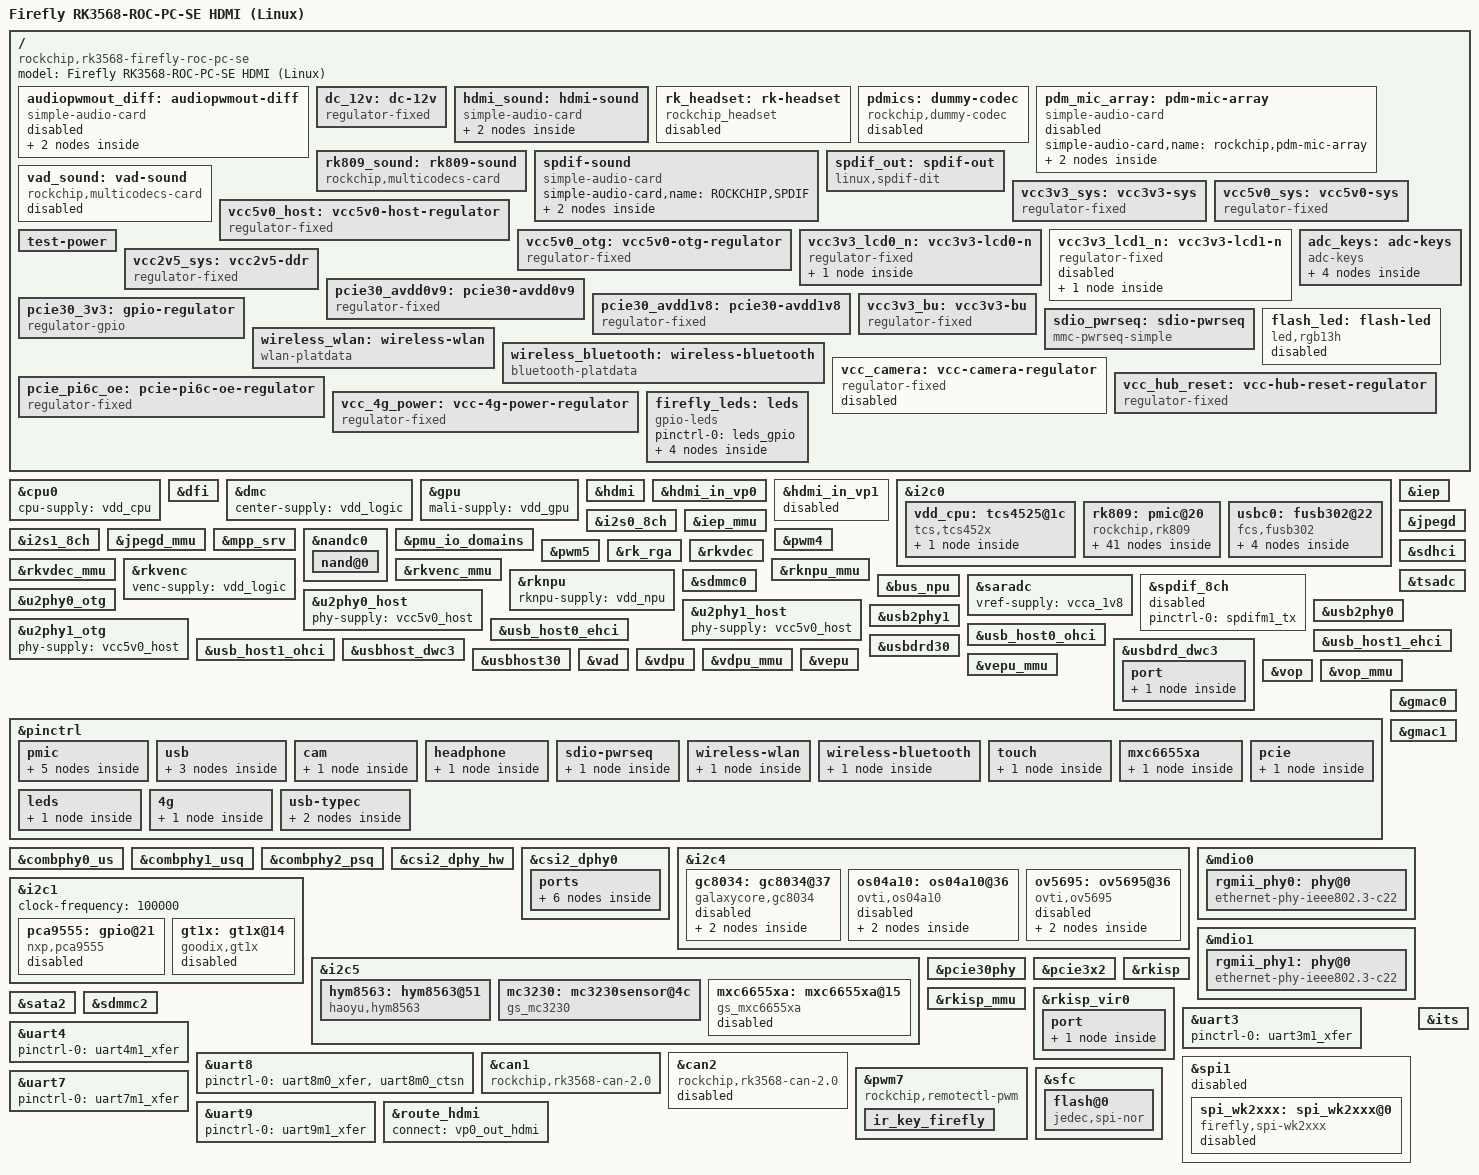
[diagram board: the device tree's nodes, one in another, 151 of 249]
// SPDX-License-Identifier: (GPL-2.0+ OR MIT)
/*
 * Copyright (c) 2020 Rockchip Electronics Co., Ltd.
 *
 */

/dts-v1/;

#include "dt-bindings/usb/pd.h"
#include <dt-bindings/pwm/pwm.h>
#include <dt-bindings/gpio/gpio.h>
#include <dt-bindings/input/rk-input.h>
#include <dt-bindings/pinctrl/rockchip.h>
#include <dt-bindings/display/rockchip_vop.h>
#include <dt-bindings/display/drm_mipi_dsi.h>
#include <dt-bindings/sensor-dev.h>
#include "rk3568.dtsi"
#include "rk3568-linux.dtsi"

/ {
	model = "Firefly RK3568-ROC-PC-SE HDMI (Linux)";
	compatible = "rockchip,rk3568-firefly-roc-pc-se", "rockchip,rk3568";

	audiopwmout_diff: audiopwmout-diff {
		status = "disabled";
		compatible = "simple-audio-card";
		simple-audio-card,format = "i2s";
		simple-audio-card,name = "rockchip,audiopwmout-diff";
		simple-audio-card,mclk-fs = <256>;
		simple-audio-card,bitclock-master = <&master>;
		simple-audio-card,frame-master = <&master>;
		simple-audio-card,cpu {
			sound-dai = <&i2s3_2ch>;
		};
		master: simple-audio-card,codec {
			sound-dai = <&dig_acodec>;
		};
	};

	dc_12v: dc-12v {
		compatible = "regulator-fixed";
		regulator-name = "dc_12v";
		regulator-always-on;
		regulator-boot-on;
		regulator-min-microvolt = <12000000>;
		regulator-max-microvolt = <12000000>;
	};

	hdmi_sound: hdmi-sound {
		compatible = "simple-audio-card";
		simple-audio-card,format = "i2s";
		simple-audio-card,mclk-fs = <128>;
		simple-audio-card,name = "rockchip,hdmi";
		status = "disabled";

		simple-audio-card,cpu {
				sound-dai = <&i2s0_8ch>;
		};
		simple-audio-card,codec {
				sound-dai = <&hdmi>;
		};
	};

	rk_headset: rk-headset {
		status = "disabled";
		compatible = "rockchip_headset";
		headset_gpio = <&gpio3 RK_PC2 GPIO_ACTIVE_LOW>;
		pinctrl-names = "default";
		pinctrl-0 = <&hp_det>;
	};

	pdmics: dummy-codec {
		status = "disabled";
		compatible = "rockchip,dummy-codec";
		#sound-dai-cells = <0>;
	};

	pdm_mic_array: pdm-mic-array {
		status = "disabled";
		compatible = "simple-audio-card";
		simple-audio-card,name = "rockchip,pdm-mic-array";
		simple-audio-card,cpu {
			sound-dai = <&pdm>;
		};
		simple-audio-card,codec {
			sound-dai = <&pdmics>;
		};
	};

	rk809_sound: rk809-sound {
		status = "okay";
		compatible = "rockchip,multicodecs-card";
		rockchip,card-name = "rockchip-rk809";
		rockchip,format = "i2s";
		rockchip,mclk-fs = <256>;
		rockchip,cpu = <&i2s1_8ch>;
		rockchip,codec = <&rk809_codec>;
	};

	spdif-sound {
		status = "okay";
		compatible = "simple-audio-card";
		simple-audio-card,name = "ROCKCHIP,SPDIF";
		simple-audio-card,cpu {
				sound-dai = <&spdif_8ch>;
		};
		simple-audio-card,codec {
				sound-dai = <&spdif_out>;
		};
	};

	spdif_out: spdif-out {
			status = "okay";
			compatible = "linux,spdif-dit";
			#sound-dai-cells = <0>;
	};

	vad_sound: vad-sound {
		status = "disabled";
		compatible = "rockchip,multicodecs-card";
		rockchip,card-name = "rockchip,rk3568-vad";
		rockchip,cpu = <&i2s1_8ch>;
		rockchip,codec = <&rk809_codec>, <&vad>;
	};

	vcc3v3_sys: vcc3v3-sys {
		compatible = "regulator-fixed";
		regulator-name = "vcc3v3_sys";
		regulator-always-on;
		regulator-boot-on;
		regulator-min-microvolt = <3300000>;
		regulator-max-microvolt = <3300000>;
		vin-supply = <&dc_12v>;
	};

	vcc5v0_sys: vcc5v0-sys {
		compatible = "regulator-fixed";
		regulator-name = "vcc5v0_sys";
		regulator-always-on;
		regulator-boot-on;
		regulator-min-microvolt = <5000000>;
		regulator-max-microvolt = <5000000>;
		vin-supply = <&dc_12v>;
	};

	vcc5v0_host: vcc5v0-host-regulator {
		compatible = "regulator-fixed";
		enable-active-high;
		gpio = <&gpio0 RK_PD6 GPIO_ACTIVE_HIGH>;
		pinctrl-names = "default";
		pinctrl-0 = <&vcc5v0_host_en>;
		regulator-name = "vcc5v0_host";
		regulator-always-on;
		regulator-boot-on;
	};

	vcc5v0_otg: vcc5v0-otg-regulator {
		compatible = "regulator-fixed";
		enable-active-high;
		gpio = <&gpio0 RK_PA5 GPIO_ACTIVE_HIGH>;
		pinctrl-names = "default";
		pinctrl-0 = <&vcc5v0_otg_en>;
		regulator-name = "vcc5v0_otg";
	};

	vcc3v3_lcd0_n: vcc3v3-lcd0-n {
		compatible = "regulator-fixed";
		regulator-name = "vcc3v3_lcd0_n";
		regulator-boot-on;
		regulator-state-mem {
			regulator-off-in-suspend;
		};
	};

	vcc3v3_lcd1_n: vcc3v3-lcd1-n {
		compatible = "regulator-fixed";
		regulator-name = "vcc3v3_lcd1_n";
		regulator-boot-on;
		regulator-state-mem {
			regulator-off-in-suspend;
		};
	};

	test-power {
		status = "okay";
	};
	
	adc_keys: adc-keys {
		compatible = "adc-keys";
		io-channels = <&saradc 0>;
		io-channel-names = "buttons";
		keyup-threshold-microvolt = <1800000>;
		poll-interval = <100>;

		recovery-key {
			label = "F12";
			linux,code = <KEY_F12>;
			press-threshold-microvolt = <1750>;
		};

		vol-down-key {
			label = "volume down";
			linux,code = <KEY_VOLUMEDOWN>;
			press-threshold-microvolt = <297500>;
		};

		menu-key {
			label = "menu";
			linux,code = <KEY_MENU>;
			press-threshold-microvolt = <980000>;
		};

		back-key {
			label = "back";
			linux,code = <KEY_BACK>;
			press-threshold-microvolt = <1305500>;
		};
	};

	vcc2v5_sys: vcc2v5-ddr {
		compatible = "regulator-fixed";
		regulator-name = "vcc2v5-sys";
		regulator-always-on;
		regulator-boot-on;
		regulator-min-microvolt = <2500000>;
		regulator-max-microvolt = <2500000>;
		vin-supply = <&vcc3v3_sys>;
	};

	pcie30_avdd0v9: pcie30-avdd0v9 {
		compatible = "regulator-fixed";
		regulator-name = "pcie30_avdd0v9";
		regulator-always-on;
		regulator-boot-on;
		regulator-min-microvolt = <900000>;
		regulator-max-microvolt = <900000>;
		vin-supply = <&vcc3v3_sys>;
	};

	pcie30_avdd1v8: pcie30-avdd1v8 {
		compatible = "regulator-fixed";
		regulator-name = "pcie30_avdd1v8";
		regulator-always-on;
		regulator-boot-on;
		regulator-min-microvolt = <1800000>;
		regulator-max-microvolt = <1800000>;
		vin-supply = <&vcc3v3_sys>;
	};

	pcie30_3v3: gpio-regulator {
		compatible = "regulator-gpio";
		regulator-name = "pcie30_3v3";
		regulator-min-microvolt = <100000>;
		regulator-max-microvolt = <3300000>;
		gpios = <&gpio0 RK_PD4 GPIO_ACTIVE_HIGH>;
		gpios-states = <0x1>;
		states = <100000 0x0
			  3300000 0x1>;
	};

	vcc3v3_bu: vcc3v3-bu {
		compatible = "regulator-fixed";
		regulator-name = "vcc3v3_bu";
		regulator-always-on;
		regulator-boot-on;
		regulator-min-microvolt = <3300000>;
		regulator-max-microvolt = <3300000>;
		vin-supply = <&vcc5v0_sys>;
	};

	sdio_pwrseq: sdio-pwrseq {
		compatible = "mmc-pwrseq-simple";
		clocks = <&rk809 1>;
		clock-names = "ext_clock";
		pinctrl-names = "default";
		pinctrl-0 = <&wifi_enable_h>;
		/*
			* On the module itself this is one of these (depending
			* on the actual card populated):
			* - SDIO_RESET_L_WL_REG_ON
			* - PDN (power down when low)
		*/
		post-power-on-delay-ms = <200>;
		reset-gpios = <&gpio3 RK_PD5 GPIO_ACTIVE_LOW>;
	};

	wireless_wlan: wireless-wlan {
		compatible = "wlan-platdata";
		rockchip,grf = <&grf>;
		wifi_chip_type = "ap6398s";
		pinctrl-names = "default";
		pinctrl-0 = <&wifi_host_wake_irq>;
		WIFI,host_wake_irq = <&gpio3 RK_PD4 GPIO_ACTIVE_HIGH>;
		status = "disabled";
	};

	wireless_bluetooth: wireless-bluetooth {
		compatible = "bluetooth-platdata";
		clocks = <&rk809 1>;
		clock-names = "ext_clock";
		//wifi-bt-power-toggle;
		uart_rts_gpios = <&gpio2 RK_PB1 GPIO_ACTIVE_LOW>;
		pinctrl-names = "default", "rts_gpio";
		pinctrl-0 = <&uart8m0_rtsn>;
		pinctrl-1 = <&uart8_gpios>;
		BT,reset_gpio    = <&gpio3 RK_PA0 GPIO_ACTIVE_HIGH>;
		BT,wake_gpio     = <&gpio3 RK_PA1 GPIO_ACTIVE_HIGH>;
		BT,wake_host_irq = <&gpio3 RK_PA2 GPIO_ACTIVE_HIGH>;
		status = "disabled";
	};

	flash_led: flash-led {
		compatible = "led,rgb13h";
		label = "pwm-flash-led";
		led-max-microamp = <20000>;
		flash-max-microamp = <20000>;
		flash-max-timeout-us = <1000000>;
		pwms = <&pwm11 0 25000 0>;
		rockchip,camera-module-index = <1>;
		rockchip,camera-module-facing = "front";
		status = "disabled";
	};

	vcc_camera: vcc-camera-regulator {
		compatible = "regulator-fixed";
		//gpio = <&pca9555 0 GPIO_ACTIVE_HIGH>;
		gpio = <&pca9555 3 GPIO_ACTIVE_HIGH>;
		pinctrl-names = "default";
		pinctrl-0 = <&vcc_cam>;
		regulator-name = "vcc_camera";
		enable-active-high;
		status = "disabled";
	};
	
	vcc5v0_host: vcc5v0-host-regulator {
		compatible = "regulator-fixed";
		enable-active-high;
		gpio = <&gpio0 RK_PA6 GPIO_ACTIVE_HIGH>;
		pinctrl-names = "default";
		pinctrl-0 = <&vcc5v0_host_en>;
		regulator-name = "vcc5v0_host";
		regulator-always-on;
	};

    vcc_hub_reset: vcc-hub-reset-regulator {
        compatible = "regulator-fixed";
        enable-active-high;
        gpio = <&gpio1 RK_PA4 GPIO_ACTIVE_HIGH>;
        pinctrl-names = "default";
        pinctrl-0 = <&vcc_hub_reset_en>;
        regulator-name = "vcc_hub_reset_en";
        regulator-always-on;
    };

    pcie_pi6c_oe: pcie-pi6c-oe-regulator {
        compatible = "regulator-fixed";
        //enable-active-high;
        gpio = <&gpio3 RK_PA7 GPIO_ACTIVE_LOW>;
        pinctrl-names = "default";
        pinctrl-0 = <&pcie_pi6c_oe_en>;
        regulator-name = "pcie_pi6c_oe_en";
        regulator-always-on;
    };

    vcc_4g_power: vcc-4g-power-regulator {
        compatible = "regulator-fixed";
        enable-active-high;
        gpio = <&gpio3 RK_PA3 GPIO_ACTIVE_HIGH>;
        pinctrl-names = "default";
        pinctrl-0 = <&vcc_4g_power_en>;
        regulator-name = "vcc_4g_power_en";
        regulator-always-on;
    };

    firefly_leds: leds {
        status = "okay";
        compatible = "gpio-leds";
        pinctrl-names = "default";
        pinctrl-0 =<&leds_gpio>;

        power_led: power {
            label = "firefly:blue:power";
            linux,default-trigger = "ir-power-click";
            default-state = "on";
            gpios = <&gpio1 RK_PB2 GPIO_ACTIVE_HIGH>;
        };

        user_led: user {
            label = "firefly:yellow:user";
            linux,default-trigger = "ir-user-click";
            default-state = "off";
            gpios = <&gpio1 RK_PB1 GPIO_ACTIVE_HIGH>;
        };

        diy1_led: diy1 {
            label = "firefly:green:diy";
            linux,default-trigger = "ir-user-click";
            default-state = "off";
            gpios = <&gpio1 RK_PB0 GPIO_ACTIVE_HIGH>;
        };

        diy2_led: diy2 {
            label = "firefly:yellow:diy";
            linux,default-trigger = "ir-user-click";
            default-state = "off";
            gpios = <&gpio2 RK_PC1 GPIO_ACTIVE_HIGH>;
        };
    };
};

&cpu0 {
	cpu-supply = <&vdd_cpu>;
};

&dfi {
	status = "okay";
};

&dmc {
	center-supply = <&vdd_logic>;
	status = "okay";
};

&gpu {
	mali-supply = <&vdd_gpu>;
	status = "okay";
};

&hdmi {
	status = "okay";
};

&hdmi_in_vp0 {
	status = "okay";
};

&hdmi_in_vp1 {
	status = "disabled";
};

&hdmi_sound {
	status = "okay";
};

&i2c0 {
	status = "okay";

	vdd_cpu: tcs4525@1c {
		compatible = "tcs,tcs452x";
		reg = <0x1c>;
		vin-supply = <&vcc5v0_sys>;
		regulator-compatible = "fan53555-reg";
		regulator-name = "vdd_cpu";
		regulator-min-microvolt = <712500>;
		regulator-max-microvolt = <1390000>;
		regulator-ramp-delay = <2300>;
		fcs,suspend-voltage-selector = <1>;
		regulator-boot-on;
		regulator-always-on;
		regulator-state-mem {
			regulator-off-in-suspend;
		};
	};

	rk809: pmic@20 {
		compatible = "rockchip,rk809";
		reg = <0x20>;
		interrupt-parent = <&gpio0>;
		interrupts = <3 IRQ_TYPE_LEVEL_LOW>;

		pinctrl-names = "default", "pmic-sleep",
				"pmic-power-off", "pmic-reset";
		pinctrl-0 = <&pmic_int>;
		pinctrl-1 = <&soc_slppin_slp>, <&rk817_slppin_slp>;
		pinctrl-2 = <&soc_slppin_gpio>, <&rk817_slppin_pwrdn>;
		pinctrl-3 = <&soc_slppin_gpio>, <&rk817_slppin_rst>;

		rockchip,system-power-controller;
		wakeup-source;
		#clock-cells = <1>;
		clock-output-names = "rk808-clkout1", "rk808-clkout2";
		//fb-inner-reg-idxs = <2>;
		/* 1: rst regs (default in codes), 0: rst the pmic */
		pmic-reset-func = <0>;
		/* not save the PMIC_POWER_EN register in uboot */
		not-save-power-en = <1>;

		vcc1-supply = <&vcc3v3_sys>;
		vcc2-supply = <&vcc3v3_sys>;
		vcc3-supply = <&vcc3v3_sys>;
		vcc4-supply = <&vcc3v3_sys>;
		vcc5-supply = <&vcc3v3_sys>;
		vcc6-supply = <&vcc3v3_sys>;
		vcc7-supply = <&vcc3v3_sys>;
		vcc8-supply = <&vcc3v3_sys>;
		vcc9-supply = <&vcc3v3_sys>;

		pwrkey {
			status = "okay";
		};

		pinctrl_rk8xx: pinctrl_rk8xx {
			gpio-controller;
			#gpio-cells = <2>;

			rk817_slppin_null: rk817_slppin_null {
				pins = "gpio_slp";
				function = "pin_fun0";
			};

			rk817_slppin_slp: rk817_slppin_slp {
				pins = "gpio_slp";
				function = "pin_fun1";
			};

			rk817_slppin_pwrdn: rk817_slppin_pwrdn {
				pins = "gpio_slp";
				function = "pin_fun2";
			};

			rk817_slppin_rst: rk817_slppin_rst {
				pins = "gpio_slp";
				function = "pin_fun3";
			};
		};

		regulators {
			vdd_logic: DCDC_REG1 {
				regulator-always-on;
				regulator-boot-on;
				regulator-min-microvolt = <500000>;
				regulator-max-microvolt = <1350000>;
				regulator-init-microvolt = <900000>;
				regulator-ramp-delay = <6001>;
				regulator-initial-mode = <0x2>;
				regulator-name = "vdd_logic";
				regulator-state-mem {
					regulator-off-in-suspend;
				};
			};

			vdd_gpu: DCDC_REG2 {
				regulator-always-on;
				regulator-boot-on;
				regulator-min-microvolt = <500000>;
				regulator-max-microvolt = <1350000>;
				regulator-init-microvolt = <900000>;
				regulator-ramp-delay = <6001>;
				regulator-initial-mode = <0x2>;
				regulator-name = "vdd_gpu";
				regulator-state-mem {
					regulator-off-in-suspend;
				};
			};

			vcc_ddr: DCDC_REG3 {
				regulator-always-on;
				regulator-boot-on;
				regulator-initial-mode = <0x2>;
				regulator-name = "vcc_ddr";
				regulator-state-mem {
					regulator-on-in-suspend;
				};
			};

			vdd_npu: DCDC_REG4 {
				regulator-always-on;
				regulator-boot-on;
				regulator-min-microvolt = <500000>;
				regulator-max-microvolt = <1350000>;
				regulator-init-microvolt = <900000>;
				regulator-ramp-delay = <6001>;
				regulator-initial-mode = <0x2>;
				regulator-name = "vdd_npu";
				regulator-state-mem {
					regulator-off-in-suspend;
				};
			};

			vdda0v9_image: LDO_REG1 {
				regulator-boot-on;
				regulator-always-on;
				regulator-min-microvolt = <900000>;
				regulator-max-microvolt = <900000>;
				regulator-name = "vdda0v9_image";
				regulator-state-mem {
					regulator-off-in-suspend;
				};
			};

			vdda_0v9: LDO_REG2 {
				regulator-always-on;
				regulator-boot-on;
				regulator-min-microvolt = <900000>;
				regulator-max-microvolt = <900000>;
				regulator-name = "vdda_0v9";
				regulator-state-mem {
					regulator-off-in-suspend;
				};
			};

			vdda0v9_pmu: LDO_REG3 {
				regulator-always-on;
				regulator-boot-on;
				regulator-min-microvolt = <900000>;
				regulator-max-microvolt = <900000>;
				regulator-name = "vdda0v9_pmu";
				regulator-state-mem {
					regulator-on-in-suspend;
					regulator-suspend-microvolt = <900000>;
				};
			};

			vccio_acodec: LDO_REG4 {
				regulator-always-on;
				regulator-boot-on;
				regulator-min-microvolt = <3300000>;
				regulator-max-microvolt = <3300000>;
				regulator-name = "vccio_acodec";
				regulator-state-mem {
					regulator-off-in-suspend;
				};
			};

			vccio_sd: LDO_REG5 {
				regulator-always-on;
				regulator-boot-on;
				regulator-min-microvolt = <1800000>;
				regulator-max-microvolt = <3300000>;
				regulator-name = "vccio_sd";
				regulator-state-mem {
					regulator-off-in-suspend;
				};
			};

			vcc3v3_pmu: LDO_REG6 {
				regulator-always-on;
				regulator-boot-on;
				regulator-min-microvolt = <3300000>;
				regulator-max-microvolt = <3300000>;
				regulator-name = "vcc3v3_pmu";
				regulator-state-mem {
					regulator-on-in-suspend;
					regulator-suspend-microvolt = <3300000>;
				};
			};

			vcca_1v8: LDO_REG7 {
				regulator-always-on;
				regulator-boot-on;
				regulator-min-microvolt = <1800000>;
				regulator-max-microvolt = <1800000>;
				regulator-name = "vcca_1v8";
				regulator-state-mem {
					regulator-off-in-suspend;
				};
			};

			vcca1v8_pmu: LDO_REG8 {
				regulator-always-on;
				regulator-boot-on;
				regulator-min-microvolt = <1800000>;
				regulator-max-microvolt = <1800000>;
				regulator-name = "vcca1v8_pmu";
				regulator-state-mem {
					regulator-on-in-suspend;
					regulator-suspend-microvolt = <1800000>;
				};
			};

			vcca1v8_image: LDO_REG9 {
				regulator-always-on;
				regulator-boot-on;
				regulator-min-microvolt = <1800000>;
				regulator-max-microvolt = <1800000>;
				regulator-name = "vcca1v8_image";
				regulator-state-mem {
					regulator-off-in-suspend;
				};
			};

			vcc_1v8: DCDC_REG5 {
				regulator-always-on;
				regulator-boot-on;
				regulator-min-microvolt = <1800000>;
				regulator-max-microvolt = <1800000>;
				regulator-name = "vcc_1v8";
				regulator-state-mem {
					regulator-off-in-suspend;
				};
			};

			vcc_3v3: SWITCH_REG1 {
				regulator-always-on;
				regulator-boot-on;
				regulator-name = "vcc_3v3";
				regulator-state-mem {
					regulator-off-in-suspend;
				};
			};

			vcc3v3_sd: SWITCH_REG2 {
				regulator-always-on;
				regulator-boot-on;
				regulator-name = "vcc3v3_sd";
				regulator-state-mem {
					regulator-off-in-suspend;
				};
			};
		};

		rk809_codec: codec {
			#sound-dai-cells = <0>;
			compatible = "rockchip,rk809-codec", "rockchip,rk817-codec";
			clocks = <&cru I2S1_MCLKOUT>;
			clock-names = "mclk";
			assigned-clocks = <&cru I2S1_MCLKOUT>, <&cru I2S1_MCLK_TX_IOE>;
			assigned-clock-rates = <12288000>;
			assigned-clock-parents = <&cru I2S1_MCLKOUT_TX>, <&cru I2S1_MCLKOUT_TX>;
			pinctrl-names = "default","spk_gpio";
			pinctrl-0 = <&i2s1m0_mclk>;
			pinctrl-1 = <&spk_ctl_gpio>;
    		hp-volume = <3>;
			spk-volume = <3>;
			mic-in-differential;
			board-spk-from-hp;

			capture-volume = <0>;
			io-channels = <&saradc 7>;
			hp-det-adc-value = <1000>;
			hp-adc-drift-scope = <100>;
			status = "okay";
		};
	};
};

&i2s0_8ch {
	status = "okay";
};

&i2s1_8ch {
	status = "okay";
	rockchip,clk-trcm = <1>;
	pinctrl-names = "default";
	pinctrl-0 = <&i2s1m0_sclktx
		     &i2s1m0_lrcktx
		     &i2s1m0_sdi0
		     &i2s1m0_sdo0>;
};

&iep {
	status = "okay";
};

&iep_mmu {
	status = "okay";
};

&jpegd {
	status = "okay";
};

&jpegd_mmu {
	status = "okay";
};

&mpp_srv {
	status = "okay";
};

&nandc0 {
	#address-cells = <1>;
	#size-cells = <0>;
	status = "okay";

	nand@0 {
		reg = <0>;
		nand-bus-width = <8>;
		nand-ecc-mode = "hw";
		nand-ecc-strength = <16>;
		nand-ecc-step-size = <1024>;
	};
};

&pmu_io_domains {
	status = "okay";
	pmuio1-supply = <&vcc3v3_pmu>;
	pmuio2-supply = <&vcc3v3_pmu>;
	vccio1-supply = <&vccio_acodec>;
	vccio3-supply = <&vccio_sd>;
	vccio4-supply = <&vcc_1v8>;
	vccio5-supply = <&vcc_3v3>;
	vccio6-supply = <&vcc_1v8>;
	vccio7-supply = <&vcc_3v3>;
};

&pwm4 {
	status = "okay";
};

&pwm5 {
	status = "okay";
};

&rk_rga {
	status = "okay";
};

&rkvdec {
	status = "okay";
};

&rkvdec_mmu {
	status = "okay";
};

&rkvenc {
	venc-supply = <&vdd_logic>;
	status = "okay";
};

&rkvenc_mmu {
	status = "okay";
};

&rknpu {
	rknpu-supply = <&vdd_npu>;
	status = "okay";
};

&rknpu_mmu {
	status = "okay";
};

&bus_npu {
	bus-supply = <&vdd_logic>;
	pvtm-supply = <&vdd_cpu>;
	status = "okay";
};

&saradc {
	status = "okay";
	vref-supply = <&vcca_1v8>;
};

&sdhci {
	bus-width = <8>;
	no-sdio;
	no-sd;
	non-removable;
	max-frequency = <200000000>;
	full-pwr-cycle-in-suspend;
	status = "okay";
};

&sdmmc0 {
	max-frequency = <150000000>;
	no-sdio;
	no-mmc;
	bus-width = <4>;
	cap-mmc-highspeed;
	cap-sd-highspeed;
	disable-wp;
	sd-uhs-sdr104;
	vmmc-supply = <&vcc3v3_sd>;
	vqmmc-supply = <&vccio_sd>;
	pinctrl-names = "default";
	pinctrl-0 = <&sdmmc0_bus4 &sdmmc0_clk &sdmmc0_cmd &sdmmc0_det>;
	status = "okay";
};

&spdif_8ch {
	status = "okay";
};

&tsadc {
	status = "okay";
};

&u2phy0_host {
	phy-supply = <&vcc5v0_host>;
	status = "okay";
};

&u2phy0_otg {
	status = "okay";
};

&u2phy1_host {
	phy-supply = <&vcc5v0_host>;
	status = "okay";
};

&u2phy1_otg {
	phy-supply = <&vcc5v0_host>;
	status = "okay";
};

&usb2phy0 {
	status = "okay";
};

&usb2phy1 {
	status = "okay";
};

&usb_host0_ehci {
	status = "okay";
};

&usb_host0_ohci {
	status = "okay";
};

&usb_host1_ehci {
	status = "okay";
};

&usb_host1_ohci {
	status = "okay";
};

&usbdrd_dwc3 {
	dr_mode = "otg";
	extcon = <&usb2phy0>;
	status = "okay";
};

&usbdrd30 {
	status = "okay";
};

&usbhost_dwc3 {
	status = "okay";
};

&usbhost30 {
	status = "okay";
};

&vad {
	rockchip,audio-src = <&i2s1_8ch>;
	rockchip,buffer-time-ms = <128>;
	rockchip,det-channel = <0>;
	rockchip,mode = <0>;
};

&vdpu {
	status = "okay";
};

&vdpu_mmu {
	status = "okay";
};

&vepu {
	status = "okay";
};

&vepu_mmu {
	status = "okay";
};

&vop {
	status = "okay";
	assigned-clocks = <&cru DCLK_VOP0>, <&cru DCLK_VOP1>;
	assigned-clock-parents = <&pmucru PLL_HPLL>, <&cru PLL_VPLL>;
};

&vop_mmu {
	status = "okay";
};

&pinctrl {

	pmic {
		pmic_int: pmic_int {
			rockchip,pins =
				<0 RK_PA3 RK_FUNC_GPIO &pcfg_pull_up>;
		};

		soc_slppin_gpio: soc_slppin_gpio {
			rockchip,pins =
				<0 RK_PA2 RK_FUNC_GPIO &pcfg_output_low_pull_down>;
		};

		soc_slppin_slp: soc_slppin_slp {
			rockchip,pins =
				<0 RK_PA2 1 &pcfg_pull_up>;
		};

		soc_slppin_rst: soc_slppin_rst {
			rockchip,pins =
				<0 RK_PA2 2 &pcfg_pull_none>;
		};

		spk_ctl_gpio: spk_ctl_gpio {
			rockchip,pins = <3 RK_PC5 RK_FUNC_GPIO &pcfg_pull_up>;
		};
	};

	usb {
		vcc5v0_host_en: vcc5v0-host-en {
			rockchip,pins = <0 RK_PD6 RK_FUNC_GPIO &pcfg_pull_none>;
		};

		vcc5v0_otg_en: vcc5v0-otg-en {
			rockchip,pins = <0 RK_PA5 RK_FUNC_GPIO &pcfg_pull_none>;
		};
	};

	cam {
		vcc_cam: vcc-cam {
			rockchip,pins =
				/* camera power en */
				<0 RK_PC1 RK_FUNC_GPIO &pcfg_pull_none>;
		};
	};
	headphone {
		hp_det: hp-det {
			rockchip,pins = <3 RK_PC2 RK_FUNC_GPIO &pcfg_pull_down>;
		};
	};

	sdio-pwrseq {
		wifi_enable_h: wifi-enable-h {
			rockchip,pins = <3 RK_PD5 RK_FUNC_GPIO &pcfg_pull_none>;
		};
	};

	wireless-wlan {
		wifi_host_wake_irq: wifi-host-wake-irq {
			rockchip,pins = <3 RK_PD4 RK_FUNC_GPIO &pcfg_pull_down>;
		};
	};

	wireless-bluetooth {
		uart8_gpios: uart8-gpios {
			rockchip,pins = <2 RK_PB1 RK_FUNC_GPIO &pcfg_pull_none>;
		};
	};

	touch {
		touch_gpio: touch-gpio {
			rockchip,pins =
				<0 RK_PB5 RK_FUNC_GPIO &pcfg_pull_up>,
				<0 RK_PB6 RK_FUNC_GPIO &pcfg_pull_none>;
		};
	};

	mxc6655xa {
		mxc6655xa_irq_gpio: mxc6655xa_irq_gpio {
			rockchip,pins = <3 RK_PC1 RK_FUNC_GPIO &pcfg_pull_none>;
		};
	};

	usb {
        vcc5v0_host_en: vcc5v0-host-en {
			rockchip,pins = <0 RK_PA6 RK_FUNC_GPIO &pcfg_pull_none>;
		};

        vcc_hub_reset_en: vcc-hub-reset-en {
            rockchip,pins = <1 RK_PA4 RK_FUNC_GPIO &pcfg_pull_none>;
        };
    };

    pcie {
        pcie_pi6c_oe_en: pcie-pi6c-oe-en {
            rockchip,pins = <3 RK_PA7 RK_FUNC_GPIO &pcfg_pull_none>;
        };
    };

    leds {
        leds_gpio: leds-gpio {
            rockchip,pins =
            /* led_power */
            <1 RK_PB2 RK_FUNC_GPIO &pcfg_pull_none>,
            /* led_user */
            <1 RK_PB1 RK_FUNC_GPIO &pcfg_pull_none>,
            /* led diy1 */
            <1 RK_PB0 RK_FUNC_GPIO &pcfg_pull_none>,
            /* led diy2 */
            <2 RK_PC1 RK_FUNC_GPIO &pcfg_pull_none>;
        };
    };

    4g {
        vcc_4g_power_en: vcc-4g-power-en {
            rockchip,pins = <3 RK_PA3 RK_FUNC_GPIO &pcfg_pull_none>;
        };
    };

	usb-typec {
		usbc0_int: usbc0-int { /*配置 FUSB302 驱动的中断 gpio pinctrl */
			rockchip,pins = <0 RK_PC1 RK_FUNC_GPIO &pcfg_pull_up>;
		};
		vcc5v0_typec0_en: vcc5v0-typec0-en { /*配置 FUSB302 驱动的 VBUSgpio pinctrl */
			rockchip,pins =<0 RK_PA5 RK_FUNC_GPIO &pcfg_pull_none>;
		};
	};
};

&combphy0_us {
	status = "okay";
};

&combphy1_usq {
	status = "okay";
};

&combphy2_psq {
	status = "okay";
};

&csi2_dphy_hw {
	status = "okay";
};

&csi2_dphy0 {
	status = "okay";

	ports {
		#address-cells = <1>;
		#size-cells = <0>;
		port@0 {
			reg = <0>;
			#address-cells = <1>;
			#size-cells = <0>;

			mipi_in_ucam0: endpoint@1 {
				reg = <1>;
				remote-endpoint = <&ucam_out0>;
				data-lanes = <1 2 3 4>;
			};
			mipi_in_ucam1: endpoint@2 {
				reg = <2>;
				remote-endpoint = <&gc8034_out>;
				data-lanes = <1 2 3 4>;
			};
			mipi_in_ucam2: endpoint@3 {
				reg = <3>;
				remote-endpoint = <&ov5695_out>;
				data-lanes = <1 2>;
			};
		};
		port@1 {
			reg = <1>;
			#address-cells = <1>;
			#size-cells = <0>;

			csidphy_out: endpoint@0 {
				reg = <0>;
				remote-endpoint = <&isp0_in>;
			};
		};
	};
};

&gmac0 {
	phy-mode = "rgmii";
	clock_in_out = "input";

	snps,reset-gpio = <&gpio2 RK_PD3 GPIO_ACTIVE_LOW>;
	snps,reset-active-low;
	/* Reset time is 20ms, 100ms for rtl8211f */
	snps,reset-delays-us = <0 20000 100000>;

	assigned-clocks = <&cru SCLK_GMAC0_RX_TX>, <&cru SCLK_GMAC0>;
	assigned-clock-parents = <&cru SCLK_GMAC0_RGMII_SPEED>, <&gmac0_clkin>;

	pinctrl-names = "default";
	pinctrl-0 = <&gmac0_miim
		     &gmac0_tx_bus2
		     &gmac0_rx_bus2
		     &gmac0_rgmii_clk
		     &gmac0_rgmii_bus
		     &gmac0_clkinout>;

	tx_delay = <0x3c>;
	rx_delay = <0x2f>;

	phy-handle = <&rgmii_phy0>;
	status = "disabled";
};

&gmac1 {
	phy-mode = "rgmii";
	clock_in_out = "input";

	snps,reset-gpio = <&gpio2 RK_PD1 GPIO_ACTIVE_LOW>;
	snps,reset-active-low;
	/* Reset time is 20ms, 100ms for rtl8211f */
	snps,reset-delays-us = <0 20000 100000>;

	assigned-clocks = <&cru SCLK_GMAC1_RX_TX>, <&cru SCLK_GMAC1>;
	assigned-clock-parents = <&cru SCLK_GMAC1_RGMII_SPEED>, <&gmac1_clkin>;

	pinctrl-names = "default";
	pinctrl-0 = <&gmac1m1_miim
		     &gmac1m1_tx_bus2
		     &gmac1m1_rx_bus2
		     &gmac1m1_rgmii_clk
		     &gmac1m1_rgmii_bus
		     &gmac1m1_clkinout>;

	tx_delay = <0x4f>;
	rx_delay = <0x26>;

	phy-handle = <&rgmii_phy1>;
	status = "disabled";
};

/*
 * power-supply should switche to vcc3v3_lcd1_n
 * when mipi panel is connected to dsi1.
 */

&i2c4 {
	status = "okay";
	gc8034: gc8034@37 {
		compatible = "galaxycore,gc8034";
		status = "disabled";
		reg = <0x37>;
		clocks = <&cru CLK_CIF_OUT>;
		clock-names = "xvclk";
		pinctrl-names = "default";
		pinctrl-0 = <&cif_clk>;
		reset-gpios = <&gpio3 RK_PB6 GPIO_ACTIVE_LOW>;
		pwdn-gpios = <&gpio4 RK_PB4 GPIO_ACTIVE_LOW>;
		rockchip,grf = <&grf>;
		rockchip,camera-module-index = <0>;
		rockchip,camera-module-facing = "back";
		rockchip,camera-module-name = "RK-CMK-8M-2-v1";
		rockchip,camera-module-lens-name = "CK8401";
		port {
			gc8034_out: endpoint {
				remote-endpoint = <&mipi_in_ucam1>;
				data-lanes = <1 2 3 4>;
			};
		};
	};
	os04a10: os04a10@36 {
		status = "disabled";
		compatible = "ovti,os04a10";
		reg = <0x36>;
		clocks = <&cru CLK_CIF_OUT>;
		clock-names = "xvclk";
		power-domains = <&power RK3568_PD_VI>;
		pinctrl-names = "default";
		pinctrl-0 = <&cif_clk>;
		reset-gpios = <&gpio3 RK_PB6 GPIO_ACTIVE_LOW>;
		pwdn-gpios = <&gpio4 RK_PB4 GPIO_ACTIVE_HIGH>;
		rockchip,camera-module-index = <0>;
		rockchip,camera-module-facing = "back";
		rockchip,camera-module-name = "CMK-OT1607-FV1";
		rockchip,camera-module-lens-name = "M12-40IRC-4MP-F16";
		port {
			ucam_out0: endpoint {
				remote-endpoint = <&mipi_in_ucam0>;
				data-lanes = <1 2 3 4>;
			};
		};
	};
	ov5695: ov5695@36 {
		status = "disabled";
		compatible = "ovti,ov5695";
		reg = <0x36>;
		clocks = <&cru CLK_CIF_OUT>;
		clock-names = "xvclk";
		power-domains = <&power RK3568_PD_VI>;
		pinctrl-names = "default";
		pinctrl-0 = <&cif_clk>;
		reset-gpios = <&gpio3 RK_PB6 GPIO_ACTIVE_HIGH>;
		pwdn-gpios = <&gpio4 RK_PB4 GPIO_ACTIVE_HIGH>;
		rockchip,camera-module-index = <0>;
		rockchip,camera-module-facing = "back";
		rockchip,camera-module-name = "TongJu";
		rockchip,camera-module-lens-name = "CHT842-MD";
		port {
			ov5695_out: endpoint {
				remote-endpoint = <&mipi_in_ucam2>;
				data-lanes = <1 2>;
			};
		};
	};
};

&i2c1 {
	status = "disabled";
	clock-frequency = <100000>;

	pca9555: gpio@21 {
		status = "disabled";
		compatible = "nxp,pca9555";
		reg = <0x21>;
		gpio-controller;
		#gpio-cells = <2>;
		gpio-group-num = <200>;
	};

	gt1x: gt1x@14 {
		status = "disabled";
		compatible = "goodix,gt1x";
		reg = <0x14>;
		pinctrl-names = "default";
		pinctrl-0 = <&touch_gpio>;
		goodix,rst-gpio = <&gpio0 RK_PB6 GPIO_ACTIVE_HIGH>;
		goodix,irq-gpio = <&gpio0 RK_PB5 IRQ_TYPE_LEVEL_LOW>;
	};
};

&i2c5 {
	status = "disabled";

	hym8563: hym8563@51 {
		status = "disabled";
		compatible = "haoyu,hym8563";
		reg = <0x51>;
		#clock-cells = <0>;
		rtc-irq-gpio = <&gpio0 RK_PD3 IRQ_TYPE_EDGE_FALLING>;
		clock-frequency = <32768>;
		//clock-output-names = "xin32k";
		/* rtc_int is not connected */
	};

	mc3230: mc3230sensor@4c {
		compatible = "gs_mc3230";
		reg = <0x4c>;
		type = <SENSOR_TYPE_ACCEL>;
		irq_enable = <0>;
		poll_delay_ms = <30>;
		layout = <4>;
		status = "disabled";
	};

	mxc6655xa: mxc6655xa@15 {
		status = "disabled";
		compatible = "gs_mxc6655xa";
		pinctrl-names = "default";
		pinctrl-0 = <&mxc6655xa_irq_gpio>;
		reg = <0x15>;
		irq-gpio = <&gpio3 RK_PC1 IRQ_TYPE_LEVEL_LOW>;
		irq_enable = <0>;
		poll_delay_ms = <30>;
		type = <SENSOR_TYPE_ACCEL>;
		power-off-in-suspend = <1>;
		layout = <1>;
	};
};

&mdio0 {
	rgmii_phy0: phy@0 {
		compatible = "ethernet-phy-ieee802.3-c22";
		reg = <0x0>;
	};
};

&mdio1 {
	rgmii_phy1: phy@0 {
		compatible = "ethernet-phy-ieee802.3-c22";
		reg = <0x0>;
	};
};

&pcie30phy {
	status = "disabled";
};

&pcie3x2 {
	reset-gpios = <&gpio2 RK_PD6 GPIO_ACTIVE_HIGH>;
	vpcie3v3-supply = <&pcie30_3v3>;
	status = "disabled";
};

&rkisp {
	status = "okay";
};

&rkisp_mmu {
	status = "okay";
};

&rkisp_vir0 {
	status = "okay";

	port {
		#address-cells = <1>;
		#size-cells = <0>;

		isp0_in: endpoint@0 {
			reg = <0>;
			remote-endpoint = <&csidphy_out>;
		};
	};
};

&sata2 {
	status = "disabled";
};

&sdmmc2 {
	max-frequency = <150000000>;
	no-sd;
	no-mmc;
	bus-width = <4>;
	disable-wp;
	cap-sd-highspeed;
	cap-sdio-irq;
	keep-power-in-suspend;
	pinctrl-names = "default";
	pinctrl-0 = <&sdmmc2m0_bus4 &sdmmc2m0_cmd &sdmmc2m0_clk>;
	sd-uhs-sdr104;
	mmc-pwrseq = <&sdio_pwrseq>;
	non-removable;
	status = "disabled";
};

&spdif_8ch {
	status = "disabled";
	pinctrl-names = "default";
	pinctrl-0 = <&spdifm1_tx>;
};

&uart3 {
	status = "disabled";
	pinctrl-names = "default";
	pinctrl-0 = <&uart3m1_xfer>;
};

&uart4 {
	status = "disabled";
	pinctrl-names = "default";
	pinctrl-0 = <&uart4m1_xfer>;
};

&uart8 {
	status = "okay";
	pinctrl-names = "default";
	pinctrl-0 = <&uart8m0_xfer &uart8m0_ctsn>;
};

&can1 {
	status = "disabled";
	compatible = "rockchip,rk3568-can-2.0";
	assigned-clocks = <&cru CLK_CAN1>;
	assigned-clock-rates = <200000000>;
	pinctrl-names = "default";
	pinctrl-0 = <&can1m1_pins>;
};

&can2 {
	status = "disabled";
	compatible = "rockchip,rk3568-can-2.0";
	assigned-clocks = <&cru CLK_CAN2>;
	assigned-clock-rates = <200000000>;
	pinctrl-names = "default";
	pinctrl-0 = <&can2m0_pins>;
};

&spi1 {
	status = "disabled";
	max-freq = <48000000>;
	dev-port = <0>;
	pinctrl-0 = <&spi1m1_pins>;
	pinctrl-1 = <&spi1m1_pins_hs>;

	spi_wk2xxx: spi_wk2xxx@0{
		status = "disabled";
		compatible = "firefly,spi-wk2xxx";
		reg = <0x00>;
		spi-max-frequency = <10000000>;
		power-gpio = <&pca9555 15 GPIO_ACTIVE_HIGH>;
		reset-gpio = <&pca9555 9 GPIO_ACTIVE_HIGH>;
		irq-gpio = <&gpio0 RK_PA6 IRQ_TYPE_EDGE_FALLING>;
		cs-gpio = <&gpio3 RK_PA1 GPIO_ACTIVE_HIGH>;
		/* rk3399 driver support SPI_CPOL | SPI_CPHA | SPI_CS_HIGH */
		//spi-cpha;     /* SPI mode: CPHA=1 */
		//spi-cpol;     /* SPI mode: CPOL=1 */
		//spi-cs-high;
	};
};

&pwm7 {
	status = "disabled";

	compatible = "rockchip,remotectl-pwm";
	interrupts = <GIC_SPI 83 IRQ_TYPE_LEVEL_HIGH>;
	remote_pwm_id = <3>;
	handle_cpu_id = <1>;
	remote_support_psci = <0>;
	pinctrl-names = "default";
	pinctrl-0 = <&pwm7_pins>;

	ir_key_firefly{
		rockchip,usercode = <0xff00>;
		rockchip,key_table =
			<0xeb   KEY_POWER>,
			<0xec   KEY_MENU>,
			<0xfe   KEY_BACK>,
			<0xb7   KEY_HOME>,
			<0xa3   KEY_WWW>,
			<0xf4   KEY_VOLUMEUP>,
			<0xa7   KEY_VOLUMEDOWN>,
			<0xf8   KEY_REPLY>,
			<0xfc   KEY_UP>,
			<0xfd   KEY_DOWN>,
			<0xf1   KEY_LEFT>,
			<0xe5   KEY_RIGHT>;
	};
};

&sfc{
    pinctrl-names = "default";
    pinctrl-0 = <&fspi_pins>;
    assigned-clock-rates = <50000000>;
    status = "okay";
    flash@0 {
        compatible = "jedec,spi-nor";
        reg = <0>;
        spi-max-frequency = <50000000>;
        spi-rx-bus-width = <1>;
        spi-tx-bus-width = <1>;
    };
};

&i2c0 {
    status = "okay";

	usbc0: fusb302@22 {
			compatible = "fcs,fusb302";
			reg = <0x22>;
			interrupt-parent = <&gpio0>; /*修改 */
			//根据 FUSB302 INT 实际连接的 GPIO 进行
			// interrupts = <&gpio0 RK_PC1 IRQ_TYPE_LEVEL_LOW>;
			fcs,int_n = <&gpio0 RK_PC1 IRQ_TYPE_LEVEL_LOW>;
			fusb340-switch-gpios = <&gpio3 RK_PC2 GPIO_ACTIVE_HIGH>;
			pinctrl-names = "default";
			pinctrl-0 = <&usbc0_int>;
			vbus-supply = <&vcc5v0_otg>;
			// vbus-supply = <&vbus_typec>;
			status = "okay";
			ports {
				#address-cells = <1>;
				#size-cells = <0>;
				/*用于关联 USB 控制器,实现 USB 角色切换的功能 */
				port@0 {
					reg = <0>;
					usbc0_role_sw: endpoint@0 {
					remote-endpoint = <&dwc3_role_switch>;
					};
				};
			};
			usb_con: connector { /*用于描述 PD 协议相关信息 */
				compatible = "usb-c-connector";
				label = "USB-C";
				data-role = "dual";
				power-role = "dual";
				try-power-role = "sink";
				op-sink-microwatt = <1000000>;
				sink-pdos =
					<PDO_FIXED(5000, 2500, PDO_FIXED_USB_COMM)>;
				source-pdos =
					<PDO_FIXED(5000, 1500, PDO_FIXED_USB_COMM)>;
			};
		};
};

&usb2phy0 {
    status = "okay";
};

&usbdrd30 {
	status = "okay";
};

&usbdrd_dwc3 {
	status = "okay";
	usb-role-switch; /*用于使能 DWC3 驱动注册 USB Role Switch 回调函数 */
	port {
		#address-cells = <1>;
		#size-cells = <0>;
		dwc3_role_switch: endpoint@0 {
			reg = <0>;
			/*关联 FUSB302 ,实现USB角色切换的功能 */
			remote-endpoint = <&usbc0_role_sw>; 
		};
	};
};

&i2c1 {
    status = "okay";
};

&i2c5 {
    status = "okay";
};

&hym8563 {
    status = "okay";
};

&mc3230 {
    status = "okay";
};

&uart3 {
    status = "okay";
    pinctrl-0 = <&uart3m1_xfer>;
};

&uart4 {
    status = "okay";
    pinctrl-0 = <&uart4m1_xfer>;
};

&uart7 {
    status = "okay";
    pinctrl-0 = <&uart7m1_xfer>;
};

&uart8 {
    status = "okay";
};

&uart9 {
    status = "okay";
    pinctrl-0 = <&uart9m1_xfer>;
};

&spi1 {
    status = "disabled";
}; 
   
&spi_wk2xxx {
    status = "disabled";
};

&can1{
       status = "okay";
};

&pcie30phy {
    status = "okay";
};

&pcie3x2 {
    reset-gpios = <&gpio2 RK_PD6 GPIO_ACTIVE_HIGH>;
    vpcie3v3-supply = <&pcie30_3v3>;
    status = "okay";
};

&its {
    status = "okay";
};

&vcc3v3_lcd1_n {
    status = "disabled";
};

&gmac0 {
    status = "okay";
    tx_delay = <0x4a>;
    rx_delay = <0x2e>;
    // wolirq-gpio = <&gpio0 RK_PC4 GPIO_ACTIVE_LOW>;
};

&gmac1 {
    status = "okay";
    tx_delay = <0x3e>;
    rx_delay = <0x32>;
    // wolirq-gpio = <&gpio0 RK_PC5 GPIO_ACTIVE_LOW>;
};

&rgmii_phy0 {
    led_status_value = <0x6940>;
}; 
   
&rgmii_phy1 {
    led_status_value = <0x6940>;
}; 


&sdio_pwrseq {
    status = "okay";
    reset-gpios = <&gpio3 RK_PD5 GPIO_ACTIVE_LOW>;
    post-power-on-delay-ms = <100>;
};

/* used for wifi */
&sdmmc2 {
    status = "okay";
};

&wireless_wlan {
    wifi_chip_type = "ap6256";
    status = "okay";
};

&wireless_bluetooth {
    status = "okay";
    BT,wake_gpio     = <&gpio3 RK_PA2 GPIO_ACTIVE_HIGH>;
    BT,wake_host_irq = <&gpio3 RK_PA1 GPIO_ACTIVE_HIGH>;
};

&spdif_8ch{
    status = "disabled";
};

&rk809 {
    rtc {
        status = "disabled";
    };
};

&pwm7 {
    status = "okay";
};

&sata2 {
    status = "okay";
};

&dfi {
    status = "okay";
};

&dmc {
    status = "okay";
};

&route_hdmi {
    status = "okay";
    connect = <&vp0_out_hdmi>;
};

